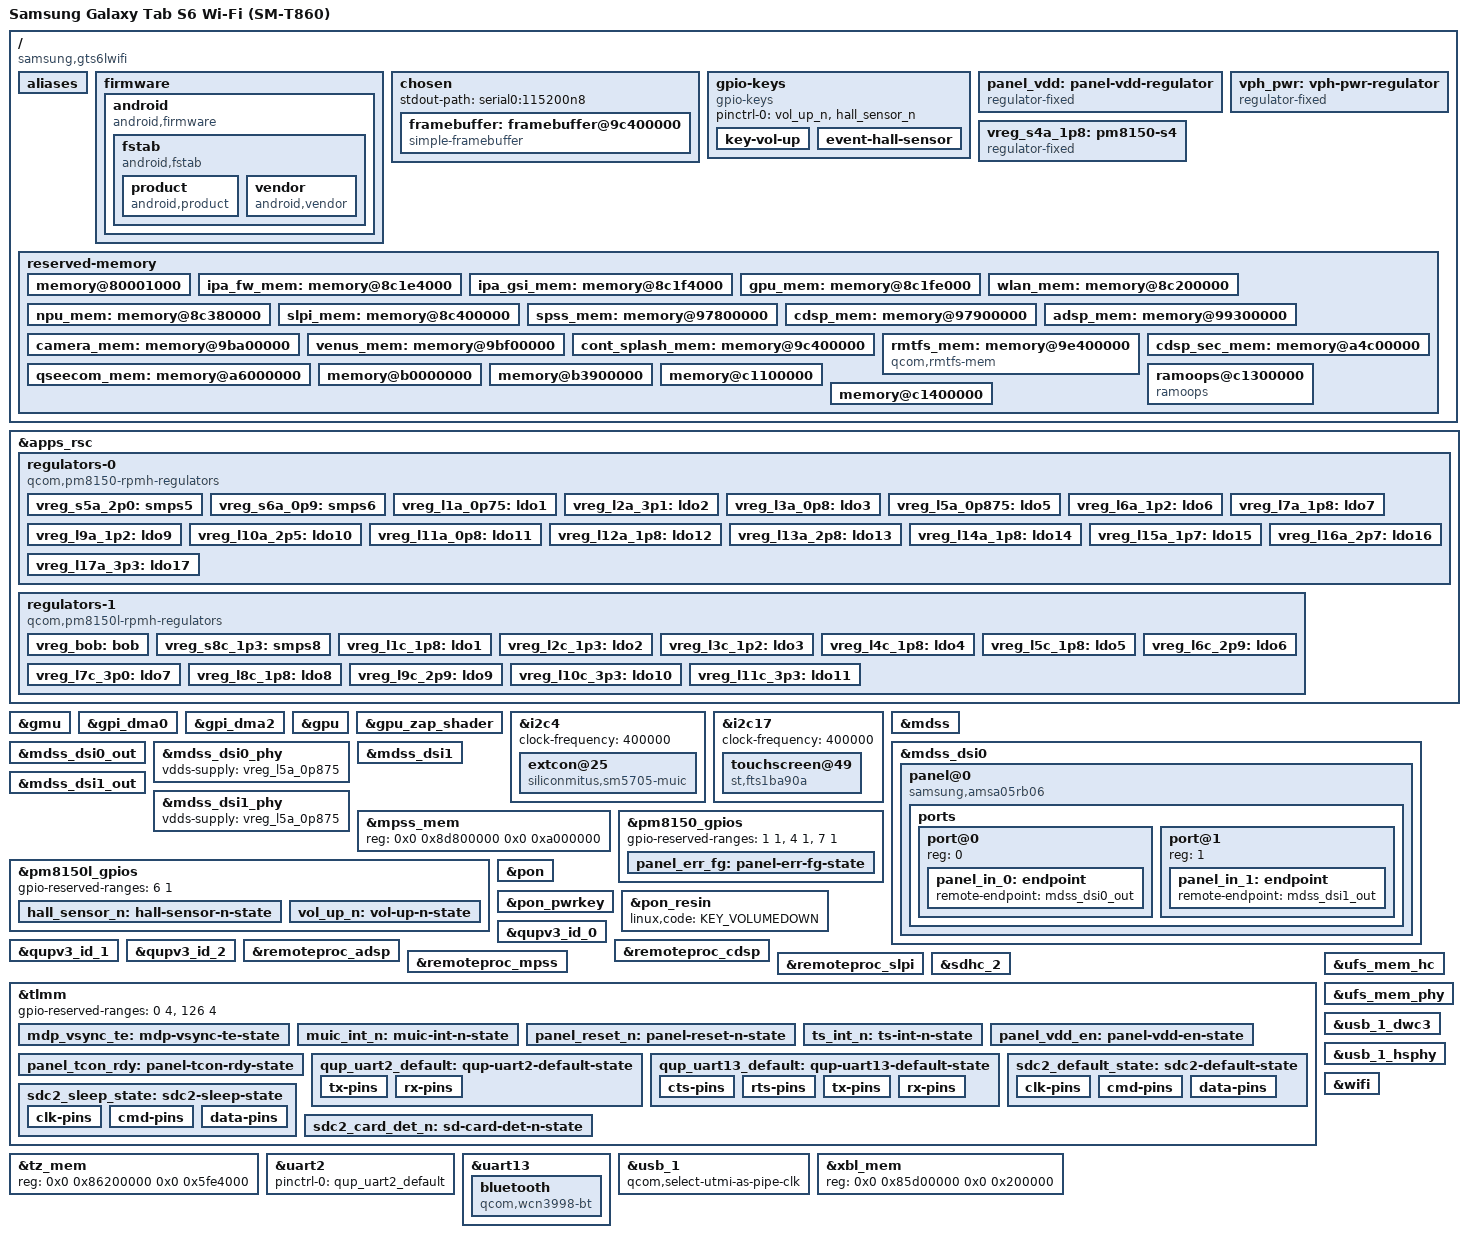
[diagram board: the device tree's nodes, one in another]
// SPDX-License-Identifier: BSD-3-Clause
/*
 * Samsung Galaxy Tab S6 Wi-Fi (SM-T860, "gts6lwifi")
 *
 * Board description derived from Samsung's SM-T860 kernel source: the
 * Qualcomm SM8150 base device trees plus Samsung's
 * sm8150-sec-gts6lwifi-overlay-r0x board overlays, which together form
 * the device tree the stock kernel runs with.
 *
 * Not described yet, for lack of a mainline driver: the Wacom W90xx
 * digitizer (i2c14 @ 0x56), the S2MM005 USB-PD controller, the SM5705
 * charger/fuel gauge/MUIC, the Cirrus Logic audio path and the pogo-pin
 * keyboard.
 */

/dts-v1/;

#include <dt-bindings/arm/qcom,ids.h>
#include <dt-bindings/gpio/gpio.h>
#include <dt-bindings/input/input.h>
#include <dt-bindings/pinctrl/qcom,pmic-gpio.h>
#include <dt-bindings/regulator/qcom,rpmh-regulator.h>
#include "sm8150.dtsi"
#include "pm8150.dtsi"
/* No PM8150B: the SM5705 charges, and SPMI SID 2 does not answer */
#include "pm8150l.dtsi"

/*
 * Samsung's firmware uses a different carve-out layout than the Qualcomm
 * reference board that sm8150.dtsi describes: TZ owns a larger region
 * and most subsystem regions moved. Drop the reference nodes that move
 * and re-create them below at the addresses the stock kernel uses.
 */
/delete-node/ &adsp_mem;
/delete-node/ &camera_mem;
/delete-node/ &cdsp_mem;
/delete-node/ &gpu_mem;
/delete-node/ &ipa_fw_mem;
/delete-node/ &ipa_gsi_mem;
/delete-node/ &npu_mem;
/delete-node/ &qseecom_mem;
/delete-node/ &rmtfs_mem;
/delete-node/ &slpi_mem;
/delete-node/ &spss_mem;
/delete-node/ &venus_mem;
/delete-node/ &wlan_mem;

/ {
	model = "Samsung Galaxy Tab S6 Wi-Fi (SM-T860)";
	compatible = "samsung,gts6lwifi", "qcom,sm8150";
	chassis-type = "tablet";

	/*
	 * With a valid dtbo partition, Samsung's bootloader picks the
	 * appended DTB by SoC ID alone and accepts board-id <0 0> as a
	 * default, as on Samsung's own base DTBs. The board is matched
	 * against the dtbo partition instead; see
	 * sm8150-samsung-gts6lwifi-dtbo.dtso.
	 */
	qcom,msm-id = <QCOM_ID_SM8150 0x20000>;
	qcom,board-id = <0 0>;

	aliases {
		serial0 = &uart2;
		serial1 = &uart13;
	};

	firmware {
		/*
		 * Android's first-stage init mounts vendor and product from
		 * here, as on stock (the bootloader cannot boot a ramdisk with
		 * system as root). /dev/block/by-name comes from
		 * androidboot.boot_devices. No AVB: the vbmeta that this
		 * kernel needs has verification disabled.
		 */
		android {
			compatible = "android,firmware";

			fstab {
				compatible = "android,fstab";

				product {
					compatible = "android,product";
					dev = "/dev/block/by-name/product";
					type = "ext4";
					mnt_flags = "ro,errors=panic";
					fsmgr_flags = "wait";
				};

				vendor {
					compatible = "android,vendor";
					dev = "/dev/block/by-name/vendor";
					type = "ext4";
					mnt_flags = "ro,barrier=1,discard";
					fsmgr_flags = "wait";
				};
			};
		};
	};

	chosen {
		#address-cells = <2>;
		#size-cells = <2>;
		ranges;

		stdout-path = "serial0:115200n8";

		/*
		 * The bootloader's splash buffer (cont_splash_mem), used until
		 * the MSM display driver takes over the panel. The panel is a
		 * command-mode panel, so updates only show if the bootloader
		 * leaves the display engine in auto-refresh. The panel's VDDIO
		 * (vreg_l14a_1p8) is always on, so it isn't listed: that way
		 * the splash, and the kernel log on it, also come up when the
		 * PM8150 regulators don't.
		 */
		framebuffer: framebuffer@9c400000 {
			compatible = "simple-framebuffer";
			reg = <0x0 0x9c400000 0x0 (2560 * 1600 * 4)>;
			width = <2560>;
			height = <1600>;
			stride = <(2560 * 4)>;
			format = "a8r8g8b8";

			clocks = <&gcc GCC_DISP_HF_AXI_CLK>,
				 <&gcc GCC_DISP_SF_AXI_CLK>;
			vdd-supply = <&panel_vdd>;
		};
	};

	gpio-keys {
		compatible = "gpio-keys";

		pinctrl-0 = <&vol_up_n>, <&hall_sensor_n>;
		pinctrl-names = "default";

		key-vol-up {
			label = "Volume Up";
			gpios = <&pm8150l_gpios 12 GPIO_ACTIVE_LOW>;
			linux,code = <KEY_VOLUMEUP>;
			debounce-interval = <15>;
			linux,can-disable;
			wakeup-source;
		};

		/* Book cover / keyboard cover magnet */
		event-hall-sensor {
			label = "Hall Effect Sensor";
			gpios = <&pm8150l_gpios 3 GPIO_ACTIVE_LOW>;
			linux,input-type = <EV_SW>;
			linux,code = <SW_LID>;
			debounce-interval = <15>;
			linux,can-disable;
			wakeup-source;
		};
	};

	/* "octa-vdd": the AMOLED panel's power, switched by a GPIO */
	panel_vdd: panel-vdd-regulator {
		compatible = "regulator-fixed";
		regulator-name = "panel_vdd";

		gpio = <&tlmm 113 GPIO_ACTIVE_HIGH>;
		enable-active-high;
		regulator-boot-on;

		pinctrl-0 = <&panel_vdd_en>;
		pinctrl-names = "default";
	};

	vph_pwr: vph-pwr-regulator {
		compatible = "regulator-fixed";
		regulator-name = "vph_pwr";
		regulator-min-microvolt = <3700000>;
		regulator-max-microvolt = <3700000>;
	};

	/*
	 * RPMh does not expose PM8150 S4: it is always on, so model it as
	 * a fixed regulator.
	 */
	vreg_s4a_1p8: pm8150-s4 {
		compatible = "regulator-fixed";
		regulator-name = "vreg_s4a_1p8";

		regulator-min-microvolt = <1800000>;
		regulator-max-microvolt = <1800000>;

		regulator-always-on;
		regulator-boot-on;

		vin-supply = <&vph_pwr>;
	};

	reserved-memory {
		/* The kernel stores its KASLR offset here for the bootloader */
		memory@80001000 {
			reg = <0x0 0x80001000 0x0 0x1000>;
			no-map;
		};

		ipa_fw_mem: memory@8c1e4000 {
			reg = <0x0 0x8c1e4000 0x0 0x10000>;
			no-map;
		};

		ipa_gsi_mem: memory@8c1f4000 {
			reg = <0x0 0x8c1f4000 0x0 0xa000>;
			no-map;
		};

		gpu_mem: memory@8c1fe000 {
			reg = <0x0 0x8c1fe000 0x0 0x2000>;
			no-map;
		};

		wlan_mem: memory@8c200000 {
			reg = <0x0 0x8c200000 0x0 0x180000>;
			no-map;
		};

		npu_mem: memory@8c380000 {
			reg = <0x0 0x8c380000 0x0 0x80000>;
			no-map;
		};

		slpi_mem: memory@8c400000 {
			reg = <0x0 0x8c400000 0x0 0x1400000>;
			no-map;
		};

		spss_mem: memory@97800000 {
			reg = <0x0 0x97800000 0x0 0x100000>;
			no-map;
		};

		cdsp_mem: memory@97900000 {
			reg = <0x0 0x97900000 0x0 0x1a00000>;
			no-map;
		};

		adsp_mem: memory@99300000 {
			reg = <0x0 0x99300000 0x0 0x2700000>;
			no-map;
		};

		camera_mem: memory@9ba00000 {
			reg = <0x0 0x9ba00000 0x0 0x500000>;
			no-map;
		};

		venus_mem: memory@9bf00000 {
			reg = <0x0 0x9bf00000 0x0 0x500000>;
			no-map;
		};

		cont_splash_mem: memory@9c400000 {
			reg = <0x0 0x9c400000 0x0 0x2000000>;
			no-map;
		};

		/*
		 * Samsung allocates rmtfs dynamically; 0x9e400000 is unused
		 * on this board because qseecom was moved out of it.
		 */
		rmtfs_mem: memory@9e400000 {
			compatible = "qcom,rmtfs-mem";
			reg = <0x0 0x9e400000 0x0 0x202000>;
			no-map;

			qcom,client-id = <1>;
			qcom,use-guard-pages;
			qcom,vmid = <QCOM_SCM_VMID_MSS_MSA>;
		};

		cdsp_sec_mem: memory@a4c00000 {
			reg = <0x0 0xa4c00000 0x0 0x1400000>;
			no-map;
		};

		qseecom_mem: memory@a6000000 {
			reg = <0x0 0xa6000000 0x0 0x2400000>;
			no-map;
		};

		/* Samsung TIMA / RKP, used by the secure world */
		memory@b0000000 {
			reg = <0x0 0xb0000000 0x0 0x400000>;
			no-map;
		};

		/* Samsung modem shared memory */
		memory@b3900000 {
			reg = <0x0 0xb3900000 0x0 0x6000000>;
			no-map;
		};

		/* Samsung platform log, read by the bootloader */
		memory@c1100000 {
			reg = <0x0 0xc1100000 0x0 0x200000>;
			no-map;
		};

		ramoops@c1300000 {
			compatible = "ramoops";
			reg = <0x0 0xc1300000 0x0 0x100000>;
			record-size = <0x40000>;
			console-size = <0x40000>;
			ftrace-size = <0x40000>;
			pmsg-size = <0x40000>;
			no-map;
		};

		/* Samsung sec_debug crash-dump area, shared with the bootloader */
		memory@c1400000 {
			reg = <0x0 0xc1400000 0x0 0x801000>;
			no-map;
		};
	};
};

&apps_rsc {
	regulators-0 {
		compatible = "qcom,pm8150-rpmh-regulators";
		qcom,pmic-id = "a";

		vdd-s1-supply = <&vph_pwr>;
		vdd-s2-supply = <&vph_pwr>;
		vdd-s3-supply = <&vph_pwr>;
		vdd-s4-supply = <&vph_pwr>;
		vdd-s5-supply = <&vph_pwr>;
		vdd-s6-supply = <&vph_pwr>;
		vdd-s7-supply = <&vph_pwr>;
		vdd-s8-supply = <&vph_pwr>;
		vdd-s9-supply = <&vph_pwr>;
		vdd-s10-supply = <&vph_pwr>;

		vdd-l1-l8-l11-supply = <&vreg_s6a_0p9>;
		vdd-l2-l10-supply = <&vreg_bob>;
		vdd-l3-l4-l5-l18-supply = <&vreg_s6a_0p9>;
		vdd-l6-l9-supply = <&vreg_s8c_1p3>;
		vdd-l7-l12-l14-l15-supply = <&vreg_s5a_2p0>;
		vdd-l13-l16-l17-supply = <&vreg_bob>;

		vreg_s5a_2p0: smps5 {
			regulator-min-microvolt = <2000000>;
			regulator-max-microvolt = <2000000>;
		};

		vreg_s6a_0p9: smps6 {
			regulator-min-microvolt = <920000>;
			regulator-max-microvolt = <1128000>;
		};

		vreg_l1a_0p75: ldo1 {
			regulator-min-microvolt = <752000>;
			regulator-max-microvolt = <752000>;
			regulator-initial-mode = <RPMH_REGULATOR_MODE_HPM>;
		};

		vreg_l2a_3p1: ldo2 {
			regulator-min-microvolt = <3072000>;
			regulator-max-microvolt = <3072000>;
			regulator-initial-mode = <RPMH_REGULATOR_MODE_HPM>;
		};

		vreg_l3a_0p8: ldo3 {
			regulator-min-microvolt = <480000>;
			regulator-max-microvolt = <932000>;
			regulator-initial-mode = <RPMH_REGULATOR_MODE_HPM>;
		};

		vreg_l5a_0p875: ldo5 {
			regulator-min-microvolt = <880000>;
			regulator-max-microvolt = <880000>;
			regulator-initial-mode = <RPMH_REGULATOR_MODE_HPM>;
		};

		vreg_l6a_1p2: ldo6 {
			regulator-min-microvolt = <1200000>;
			regulator-max-microvolt = <1200000>;
			regulator-initial-mode = <RPMH_REGULATOR_MODE_HPM>;
		};

		vreg_l7a_1p8: ldo7 {
			regulator-min-microvolt = <1800000>;
			regulator-max-microvolt = <1800000>;
			regulator-initial-mode = <RPMH_REGULATOR_MODE_HPM>;
		};

		vreg_l9a_1p2: ldo9 {
			regulator-min-microvolt = <1200000>;
			regulator-max-microvolt = <1200000>;
			regulator-initial-mode = <RPMH_REGULATOR_MODE_HPM>;
		};

		vreg_l10a_2p5: ldo10 {
			regulator-min-microvolt = <2504000>;
			regulator-max-microvolt = <2960000>;
			regulator-initial-mode = <RPMH_REGULATOR_MODE_HPM>;
		};

		vreg_l11a_0p8: ldo11 {
			regulator-min-microvolt = <800000>;
			regulator-max-microvolt = <800000>;
			regulator-initial-mode = <RPMH_REGULATOR_MODE_HPM>;
		};

		vreg_l12a_1p8: ldo12 {
			regulator-min-microvolt = <1800000>;
			regulator-max-microvolt = <1800000>;
			regulator-initial-mode = <RPMH_REGULATOR_MODE_HPM>;
		};

		/* Kept on by the stock kernel */
		vreg_l13a_2p8: ldo13 {
			regulator-min-microvolt = <2800000>;
			regulator-max-microvolt = <2900000>;
			regulator-initial-mode = <RPMH_REGULATOR_MODE_HPM>;
			regulator-always-on;
		};

		/* Panel VDDIO and touchscreen DVDD */
		vreg_l14a_1p8: ldo14 {
			regulator-min-microvolt = <1800000>;
			regulator-max-microvolt = <1800000>;
			regulator-initial-mode = <RPMH_REGULATOR_MODE_HPM>;
			regulator-always-on;
		};

		vreg_l15a_1p7: ldo15 {
			regulator-min-microvolt = <1704000>;
			regulator-max-microvolt = <1704000>;
			regulator-initial-mode = <RPMH_REGULATOR_MODE_HPM>;
		};

		vreg_l16a_2p7: ldo16 {
			regulator-min-microvolt = <2704000>;
			regulator-max-microvolt = <2960000>;
			regulator-initial-mode = <RPMH_REGULATOR_MODE_HPM>;
		};

		/*
		 * Touchscreen AVDD. Stock asks for 3.3 V, which this LDO
		 * (1.504 V + n * 8 mV) cannot make: 3.3 V here would fail the
		 * whole PMIC's regulators with "unsupportable voltage
		 * constraints".
		 */
		vreg_l17a_3p3: ldo17 {
			regulator-min-microvolt = <3304000>;
			regulator-max-microvolt = <3304000>;
			regulator-initial-mode = <RPMH_REGULATOR_MODE_HPM>;
		};
	};

	regulators-1 {
		compatible = "qcom,pm8150l-rpmh-regulators";
		qcom,pmic-id = "c";

		vdd-s1-supply = <&vph_pwr>;
		vdd-s2-supply = <&vph_pwr>;
		vdd-s3-supply = <&vph_pwr>;
		vdd-s4-supply = <&vph_pwr>;
		vdd-s5-supply = <&vph_pwr>;
		vdd-s6-supply = <&vph_pwr>;
		vdd-s7-supply = <&vph_pwr>;
		vdd-s8-supply = <&vph_pwr>;

		vdd-l1-l8-supply = <&vreg_s4a_1p8>;
		vdd-l2-l3-supply = <&vreg_s8c_1p3>;
		vdd-l4-l5-l6-supply = <&vreg_bob>;
		vdd-l7-l11-supply = <&vreg_bob>;
		vdd-l9-l10-supply = <&vreg_bob>;

		vdd-bob-supply = <&vph_pwr>;
		vdd-flash-supply = <&vreg_bob>;
		vdd-rgb-supply = <&vreg_bob>;

		vreg_bob: bob {
			regulator-min-microvolt = <3008000>;
			regulator-max-microvolt = <4000000>;
			regulator-initial-mode = <RPMH_REGULATOR_MODE_AUTO>;
			regulator-allow-bypass;
		};

		vreg_s8c_1p3: smps8 {
			regulator-min-microvolt = <1352000>;
			regulator-max-microvolt = <1352000>;
		};

		vreg_l1c_1p8: ldo1 {
			regulator-min-microvolt = <1800000>;
			regulator-max-microvolt = <1800000>;
			regulator-initial-mode = <RPMH_REGULATOR_MODE_HPM>;
		};

		vreg_l2c_1p3: ldo2 {
			regulator-min-microvolt = <1304000>;
			regulator-max-microvolt = <1304000>;
			regulator-initial-mode = <RPMH_REGULATOR_MODE_HPM>;
		};

		vreg_l3c_1p2: ldo3 {
			regulator-min-microvolt = <1200000>;
			regulator-max-microvolt = <1200000>;
			regulator-initial-mode = <RPMH_REGULATOR_MODE_HPM>;
		};

		vreg_l4c_1p8: ldo4 {
			regulator-min-microvolt = <1704000>;
			regulator-max-microvolt = <2928000>;
			regulator-initial-mode = <RPMH_REGULATOR_MODE_HPM>;
		};

		vreg_l5c_1p8: ldo5 {
			regulator-min-microvolt = <1704000>;
			regulator-max-microvolt = <2928000>;
			regulator-initial-mode = <RPMH_REGULATOR_MODE_HPM>;
		};

		/* microSD card I/O */
		vreg_l6c_2p9: ldo6 {
			regulator-min-microvolt = <1800000>;
			regulator-max-microvolt = <2960000>;
			regulator-initial-mode = <RPMH_REGULATOR_MODE_HPM>;
		};

		vreg_l7c_3p0: ldo7 {
			regulator-min-microvolt = <3000000>;
			regulator-max-microvolt = <3312000>;
			regulator-initial-mode = <RPMH_REGULATOR_MODE_HPM>;
		};

		vreg_l8c_1p8: ldo8 {
			regulator-min-microvolt = <1800000>;
			regulator-max-microvolt = <1800000>;
			regulator-initial-mode = <RPMH_REGULATOR_MODE_HPM>;
		};

		/* microSD card VDD */
		vreg_l9c_2p9: ldo9 {
			regulator-min-microvolt = <2704000>;
			regulator-max-microvolt = <2960000>;
			regulator-initial-mode = <RPMH_REGULATOR_MODE_HPM>;
		};

		vreg_l10c_3p3: ldo10 {
			regulator-min-microvolt = <3000000>;
			regulator-max-microvolt = <3312000>;
			regulator-initial-mode = <RPMH_REGULATOR_MODE_HPM>;
		};

		/*
		 * WCN3998 CH0 (Bluetooth and Wi-Fi). Neither of their drivers
		 * asks for a voltage, and with a range the regulator core
		 * doesn't set one either, so RPMh got no vote for it at all;
		 * stock runs it at 3.312 V.
		 */
		vreg_l11c_3p3: ldo11 {
			regulator-min-microvolt = <3312000>;
			regulator-max-microvolt = <3312000>;
			regulator-initial-mode = <RPMH_REGULATOR_MODE_HPM>;
		};
	};
};

&gmu {
	status = "okay";
};

&gpi_dma0 {
	status = "okay";
};

&gpi_dma2 {
	status = "okay";
};

&gpu {
	status = "okay";
};

&gpu_zap_shader {
	/* Samsung-signed, so it has to come from the tablet (see below) */
	firmware-name = "qcom/sm8150/samsung/gts6lwifi/a640_zap.mdt";
};

&i2c4 {
	clock-frequency = <400000>;

	status = "okay";

	/* USB D+/D- switch: USB has no data lines until this connects them */
	extcon@25 {
		compatible = "siliconmitus,sm5705-muic";
		reg = <0x25>;

		interrupts-extended = <&tlmm 122 IRQ_TYPE_LEVEL_LOW>;
		pinctrl-0 = <&muic_int_n>;
		pinctrl-names = "default";
	};
};

&i2c17 {
	clock-frequency = <400000>;

	status = "okay";

	touchscreen@49 {
		compatible = "st,fts1ba90a";
		reg = <0x49>;

		interrupts-extended = <&tlmm 87 IRQ_TYPE_LEVEL_LOW>;
		pinctrl-0 = <&ts_int_n>;
		pinctrl-names = "default";

		avdd-supply = <&vreg_l17a_3p3>;
		vdd-supply = <&vreg_l14a_1p8>;

		/*
		 * The controller reports in portrait (1600x2560): turn that
		 * into the panel's landscape scan, x = raw y, y = 1599 - raw x
		 */
		touchscreen-size-x = <1600>;
		touchscreen-size-y = <2560>;
		touchscreen-inverted-x;
		touchscreen-swapped-x-y;
	};
};

&mdss {
	status = "okay";
};

/*
 * The panel is one display driver IC with two DSI inputs, each fed one
 * 1280x1600 half. Commands go to it over DSI0 only, so the links are
 * bonded but not synced (no qcom,sync-dual-dsi).
 */
&mdss_dsi0 {
	vdda-supply = <&vreg_l3c_1p2>;

	qcom,dual-dsi-mode;
	qcom,master-dsi;
	/* Anapass DDI: LP-11 through reset and TCON_RDY, then the HS clock */
	qcom,defer-continuous-clock;

	pinctrl-0 = <&mdp_vsync_te>;
	pinctrl-names = "default";

	status = "okay";

	panel@0 {
		compatible = "samsung,amsa05rb06";
		reg = <0>;

		vddio-supply = <&vreg_l14a_1p8>;
		vdd-supply = <&panel_vdd>;
		reset-gpios = <&tlmm 59 GPIO_ACTIVE_LOW>;
		tcon-rdy-gpios = <&tlmm 140 GPIO_ACTIVE_HIGH>;
		err-fg-gpios = <&pm8150_gpios 1 GPIO_ACTIVE_LOW>;

		pinctrl-0 = <&panel_reset_n>, <&panel_tcon_rdy>, <&panel_err_fg>;
		pinctrl-names = "default";

		ports {
			#address-cells = <1>;
			#size-cells = <0>;

			port@0 {
				reg = <0>;

				panel_in_0: endpoint {
					remote-endpoint = <&mdss_dsi0_out>;
				};
			};

			port@1 {
				reg = <1>;

				panel_in_1: endpoint {
					remote-endpoint = <&mdss_dsi1_out>;
				};
			};
		};
	};
};

&mdss_dsi0_out {
	remote-endpoint = <&panel_in_0>;
	data-lanes = <0 1 2 3>;
};

&mdss_dsi0_phy {
	vdds-supply = <&vreg_l5a_0p875>;

	status = "okay";
};

&mdss_dsi1 {
	vdda-supply = <&vreg_l3c_1p2>;

	qcom,dual-dsi-mode;
	qcom,defer-continuous-clock;

	/* DSI1 is the slave link and runs from DSI0's PLL */
	assigned-clock-parents = <&mdss_dsi0_phy DSI_BYTE_PLL_CLK>,
				 <&mdss_dsi0_phy DSI_PIXEL_PLL_CLK>;

	status = "okay";
};

&mdss_dsi1_out {
	remote-endpoint = <&panel_in_1>;
	data-lanes = <0 1 2 3>;
};

&mdss_dsi1_phy {
	vdds-supply = <&vreg_l5a_0p875>;

	status = "okay";
};

/* Same base as the reference design, 16 MiB larger */
&mpss_mem {
	reg = <0x0 0x8d800000 0x0 0xa000000>;
};

&pm8150_gpios {
	/* Not owned by the application processor (qcom,gpios-disallowed) */
	gpio-reserved-ranges = <1 1>, <4 1>, <7 1>;

	/* ERR_FG, the panel's ESD detect output: high, low on an error */
	panel_err_fg: panel-err-fg-state {
		pins = "gpio1";
		function = "normal";
		bias-disable;
		input-enable;
	};
};

&pm8150l_gpios {
	/* Not owned by the application processor (qcom,gpios-disallowed) */
	gpio-reserved-ranges = <6 1>;

	hall_sensor_n: hall-sensor-n-state {
		pins = "gpio3";
		function = "normal";
		power-source = <0>;
		bias-disable;
		input-enable;
	};

	vol_up_n: vol-up-n-state {
		pins = "gpio12";
		function = "normal";
		power-source = <0>;
		bias-pull-up;
		input-enable;
	};
};

&pon {
	/* Restart reasons the bootloader understands */
	mode-bootloader = <0x2>;
	mode-recovery = <0x1>;
};

&pon_pwrkey {
	status = "okay";
};

&pon_resin {
	linux,code = <KEY_VOLUMEDOWN>;

	status = "okay";
};

&qupv3_id_0 {
	status = "okay";
};

&qupv3_id_1 {
	status = "okay";
};

&qupv3_id_2 {
	status = "okay";
};

/*
 * The signed firmware is in the stock firmware partition (apnhlos). The
 * AOSP build mounts it at /mnt/vendor/apnhlos and links its image/
 * directory as /vendor/firmware/qcom/sm8150/samsung/gts6lwifi, under
 * firmware_class.path=/vendor/firmware, next to the linux-firmware files
 * in /vendor/firmware/qcom.
 */
&remoteproc_adsp {
	firmware-name = "qcom/sm8150/samsung/gts6lwifi/adsp.mdt";

	status = "okay";
};

&remoteproc_cdsp {
	firmware-name = "qcom/sm8150/samsung/gts6lwifi/cdsp.mdt";

	status = "okay";
};

/*
 * The modem's firmware is on its own partition (modem), not in apnhlos. It
 * also runs the WCN3998's WLAN firmware, which it fetches over QRTR from
 * tqftpserv, and tqftpserv looks for that next to the modem firmware: the
 * AOSP build puts the two together in this directory.
 */
&remoteproc_mpss {
	firmware-name = "qcom/sm8150/samsung/gts6lwifi-modem/modem.mdt";

	status = "okay";
};

&remoteproc_slpi {
	firmware-name = "qcom/sm8150/samsung/gts6lwifi/slpi.mdt";

	status = "okay";
};

&sdhc_2 {
	cd-gpios = <&tlmm 96 GPIO_ACTIVE_LOW>;

	pinctrl-0 = <&sdc2_default_state>, <&sdc2_card_det_n>;
	pinctrl-1 = <&sdc2_sleep_state>, <&sdc2_card_det_n>;
	pinctrl-names = "default", "sleep";

	vmmc-supply = <&vreg_l9c_2p9>;
	vqmmc-supply = <&vreg_l6c_2p9>;

	bus-width = <4>;
	no-sdio;
	no-mmc;

	status = "okay";
};

&tlmm {
	/*
	 * GPIOs 0-3 are the secure fingerprint-sensor SPI bus (QUP SE0);
	 * 126-129 are reserved on the reference design as well.
	 */
	gpio-reserved-ranges = <0 4>, <126 4>;

	mdp_vsync_te: mdp-vsync-te-state {
		pins = "gpio8";
		function = "mdp_vsync";
		drive-strength = <2>;
		bias-pull-down;
	};

	muic_int_n: muic-int-n-state {
		pins = "gpio122";
		function = "gpio";
		drive-strength = <2>;
		bias-disable;
	};

	panel_reset_n: panel-reset-n-state {
		pins = "gpio59";
		function = "gpio";
		drive-strength = <8>;
		bias-disable;
	};

	ts_int_n: ts-int-n-state {
		pins = "gpio87";
		function = "gpio";
		drive-strength = <2>;
		bias-disable;
	};

	panel_vdd_en: panel-vdd-en-state {
		pins = "gpio113";
		function = "gpio";
		drive-strength = <2>;
		bias-disable;
	};

	panel_tcon_rdy: panel-tcon-rdy-state {
		pins = "gpio140";
		function = "gpio";
		drive-strength = <8>;
		bias-pull-down;
	};

	qup_uart2_default: qup-uart2-default-state {
		tx-pins {
			pins = "gpio85";
			function = "qup12";
			drive-strength = <2>;
			bias-pull-up;
		};

		rx-pins {
			pins = "gpio86";
			function = "qup12";
			drive-strength = <2>;
			bias-pull-down;
		};
	};

	/*
	 * As Samsung sets them up, in the one state for the port open and
	 * closed: the WCN3998 takes its power-on and power-off commands as
	 * pulses on its UART RX line (our TX), so TX stays with the UART and
	 * pulled up while the port is closed and reopened around the power-on
	 * pulse, rather than being handed to the GPIO block in between.
	 */
	qup_uart13_default: qup-uart13-default-state {
		cts-pins {
			pins = "gpio43";
			function = "qup13";
			drive-strength = <2>;
			bias-disable;
		};

		rts-pins {
			pins = "gpio44";
			function = "qup13";
			drive-strength = <2>;
			bias-pull-down;
		};

		tx-pins {
			pins = "gpio45";
			function = "qup13";
			drive-strength = <2>;
			bias-pull-up;
		};

		rx-pins {
			pins = "gpio46";
			function = "qup13";
			drive-strength = <2>;
			bias-disable;
		};
	};

	sdc2_default_state: sdc2-default-state {
		clk-pins {
			pins = "sdc2_clk";
			drive-strength = <16>;
			bias-disable;
		};

		cmd-pins {
			pins = "sdc2_cmd";
			drive-strength = <8>;
			bias-pull-up;
		};

		data-pins {
			pins = "sdc2_data";
			drive-strength = <8>;
			bias-pull-up;
		};
	};

	sdc2_sleep_state: sdc2-sleep-state {
		clk-pins {
			pins = "sdc2_clk";
			drive-strength = <2>;
			bias-disable;
		};

		cmd-pins {
			pins = "sdc2_cmd";
			drive-strength = <2>;
			bias-pull-up;
		};

		data-pins {
			pins = "sdc2_data";
			drive-strength = <2>;
			bias-pull-up;
		};
	};

	sdc2_card_det_n: sd-card-det-n-state {
		pins = "gpio96";
		function = "gpio";
		drive-strength = <2>;
		bias-disable;
	};
};

/* The TZ region is larger than on the reference design */
&tz_mem {
	reg = <0x0 0x86200000 0x0 0x5fe4000>;
};

&uart2 {
	pinctrl-0 = <&qup_uart2_default>;
	pinctrl-names = "default";

	status = "okay";
};

&uart13 {
	/delete-property/ interrupts;
	interrupts-extended = <&intc GIC_SPI 585 IRQ_TYPE_LEVEL_HIGH>,
			      <&tlmm 46 IRQ_TYPE_EDGE_FALLING>;
	pinctrl-0 = <&qup_uart13_default>;
	pinctrl-names = "default";

	status = "okay";

	bluetooth {
		compatible = "qcom,wcn3998-bt";

		vddio-supply = <&vreg_s4a_1p8>;
		vddxo-supply = <&vreg_l7a_1p8>;
		vddrf-supply = <&vreg_l2c_1p3>;
		vddch0-supply = <&vreg_l11c_3p3>;
	};
};

&ufs_mem_hc {
	reset-gpios = <&tlmm 175 GPIO_ACTIVE_LOW>;

	vcc-supply = <&vreg_l10a_2p5>;
	vcc-max-microamp = <750000>;
	vccq-supply = <&vreg_l9a_1p2>;
	vccq-max-microamp = <700000>;
	vccq2-supply = <&vreg_s4a_1p8>;
	vccq2-max-microamp = <750000>;

	status = "okay";
};

&ufs_mem_phy {
	vdda-phy-supply = <&vreg_l5a_0p875>;
	vdda-pll-supply = <&vreg_l3c_1p2>;

	status = "okay";
};

/*
 * USB-C orientation and roles are handled by the S2MM005 PD controller,
 * which has no mainline driver, so run the port as a USB 2.0 device only.
 */
&usb_1 {
	qcom,select-utmi-as-pipe-clk;

	status = "okay";
};

&usb_1_dwc3 {
	dr_mode = "peripheral";
	maximum-speed = "high-speed";
	phys = <&usb_1_hsphy>;
	phy-names = "usb2-phy";
};

&usb_1_hsphy {
	vdda-pll-supply = <&vreg_l5a_0p875>;
	vdda18-supply = <&vreg_l12a_1p8>;
	vdda33-supply = <&vreg_l2a_3p1>;

	status = "okay";
};

&wifi {
	vdd-0.8-cx-mx-supply = <&vreg_l1a_0p75>;
	vdd-1.8-xo-supply = <&vreg_l7a_1p8>;
	vdd-1.3-rfa-supply = <&vreg_l2c_1p3>;
	vdd-3.3-ch0-supply = <&vreg_l11c_3p3>;

	status = "okay";
};

/*
 * Samsung describes a single XBL/AOP region at 0x85e00000; cover both
 * it and the reference board's XBL region in front of it.
 */
&xbl_mem {
	reg = <0x0 0x85d00000 0x0 0x200000>;
};
